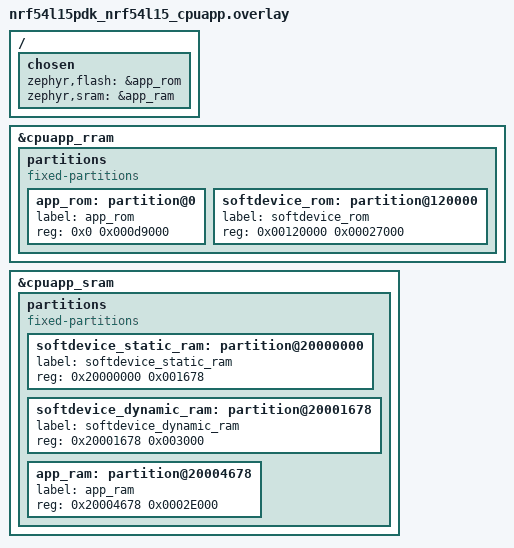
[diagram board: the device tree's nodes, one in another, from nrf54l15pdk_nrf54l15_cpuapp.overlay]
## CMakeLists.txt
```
#
# Copyright (c) 2024 Nordic Semiconductor ASA
#
# SPDX-License-Identifier: LicenseRef-Nordic-5-Clause
#

cmake_minimum_required(VERSION 3.20.0)

find_package(Zephyr REQUIRED HINTS $ENV{ZEPHYR_BASE})
project(hello_softdevice)

target_sources(app PRIVATE src/main.c)
```

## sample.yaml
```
sample:
  name: SoftDevice handler sample
tests:
  sample.sd_handler:
    sysbuild: true
    build_only: true
    integration_platforms:
      - lite_nrf52840/nrf52840
      - lite_nrf54l15/nrf54l15/cpuapp
    platform_allow:
      - lite_nrf52840/nrf52840
      - lite_nrf54l15/nrf54l15/cpuapp
    tags: ci_build
```

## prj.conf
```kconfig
CONFIG_LOG=y
CONFIG_LOG_BACKEND_LITE_UARTE=y
CONFIG_CONSOLE=y
CONFIG_LITE_UARTE_CONSOLE=y

CONFIG_SOFTDEVICE=y
```

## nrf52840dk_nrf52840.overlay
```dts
&flash0 {
	partitions {
		compatible = "fixed-partitions";
		#address-cells = <1>;
		#size-cells = <1>;
		softdevice: partition@0 {
			label = "sd";
			reg = <0x00000000 0x00027000>;
		};
		app_rom: partition@27000 {
			label = "app";
			reg = <0x00027000 0x000d9000>;
		};
	};
};

&sram0 {
	reg = <0x20003400 DT_SIZE_K(200)>;
};


/ {
	chosen {
		zephyr,flash = &app_rom;
		zephyr,sram = &sram0;
	};
};
```

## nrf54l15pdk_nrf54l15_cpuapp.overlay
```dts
/delete-node/ &boot_partition;
/delete-node/ &slot0_partition;
/delete-node/ &slot0_ns_partition;
/delete-node/ &slot1_partition;
/delete-node/ &slot1_ns_partition;
/delete-node/ &storage_partition;

&cpuapp_rram {
	partitions {
		compatible = "fixed-partitions";
		#address-cells = <1>;
		#size-cells = <1>;

		app_rom: partition@0 {
			label = "app_rom";
			reg = <0x0 0x000d9000>;
		};
		/* Why gap ? */
		softdevice_rom: partition@120000 {
			label = "softdevice_rom";
			reg = <0x00120000 0x00027000>;
		};
	};
};
&cpuapp_sram {
	partitions {
		compatible = "fixed-partitions";
		#address-cells = <1>;
		#size-cells = <1>;
		softdevice_static_ram: partition@20000000 {
			label = "softdevice_static_ram";
			reg = <0x20000000 0x001678>;
		};
		softdevice_dynamic_ram: partition@20001678 {
			label = "softdevice_dynamic_ram";
			reg = <0x20001678 0x003000>;
		};
		app_ram: partition@20004678 {
			label = "app_ram";
			reg = <0x20004678 0x0002E000>;
		};
	};
};

/ {
	chosen {
		/delete-property/ zephyr,code-partition;
		zephyr,flash = &app_rom;
		zephyr,sram = &app_ram;
	};
};
```

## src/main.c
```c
/*
 * Copyright (c) 2024 Nordic Semiconductor ASA
 *
 * SPDX-License-Identifier: LicenseRef-Nordic-5-Clause
 */

#include <nrf_sdh.h>
#include <nrf_sdh_ble.h>
#include <nrf_sdh_soc.h>
#include <zephyr/kernel.h> /* k_busy_wait() */
#include <zephyr/sys_clock.h> /* USEC_PER_SEC */
#include <zephyr/sys/printk.h>

static void on_ble_evt(const ble_evt_t *evt, void *ctx)
{
	printk("BLE event %d\n", evt->header.evt_id);
}
NRF_SDH_BLE_OBSERVER(sdh_ble, on_ble_evt, NULL, 0);

static void on_soc_evt(uint32_t evt, void *ctx)
{
	printk("SoC event\n");
}
NRF_SDH_SOC_OBSERVER(sdh_soc, on_soc_evt, NULL, 0);

static void on_state_change(enum nrf_sdh_state_evt state, void *ctx)
{
	printk("SoftDevice state has changed to %d\n", state);
}
NRF_SDH_STATE_EVT_OBSERVER(sdh_state, on_state_change, NULL, 0);

int main(void)
{
	int err;

	printk("Hello SoftDevice sample started\n");

	err = nrf_sdh_enable_request();
	if (err) {
		printk("Failed to enable SoftDevice, err %d\n", err);
		return -1;
	}

	printk("SoftDevice enabled\n");

	err = nrf_sdh_ble_enable(CONFIG_NRF_SDH_BLE_CONN_TAG);
	if (err) {
		printk("Failed to enable BLE, err %d\n", err);
		return -1;
	}

	printk("Bluetooth enabled\n");

	k_busy_wait(2 * USEC_PER_SEC);

	err = nrf_sdh_disable_request();
	if (err) {
		printk("Failed to disable SoftDevice, err %d\n", err);
		return -1;
	}

	printk("SoftDevice disabled\n");
	printk("Bye\n");

	return 0;
}
```
